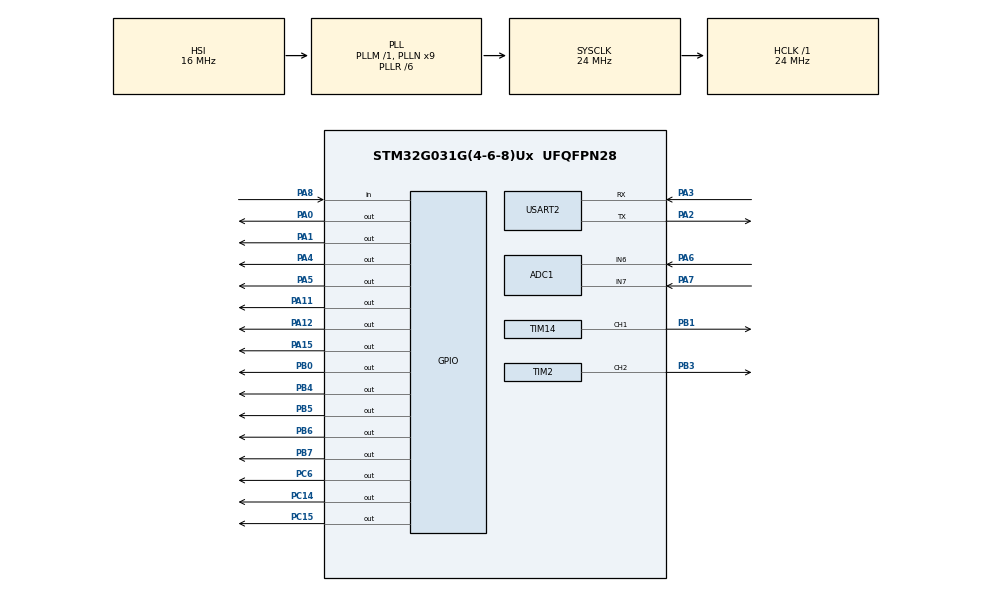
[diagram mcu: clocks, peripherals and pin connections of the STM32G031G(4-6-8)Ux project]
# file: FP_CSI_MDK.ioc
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ADC1.Channel-2\#ChannelRegularConversion=ADC_CHANNEL_6
ADC1.Channel-3\#ChannelRegularConversion=ADC_CHANNEL_7
ADC1.ClockPrescaler=ADC_CLOCK_ASYNC_DIV2
ADC1.ContinuousConvMode=ENABLE
ADC1.DMAContinuousRequests=ENABLE
ADC1.DiscontinuousConvMode=DISABLE
ADC1.EOCSelection=ADC_EOC_SEQ_CONV
ADC1.NbrOfConversion=2
ADC1.NbrOfConversionFlag=1
ADC1.Rank-2\#ChannelRegularConversion=1
ADC1.Rank-3\#ChannelRegularConversion=2
ADC1.SamplingTime-2\#ChannelRegularConversion=ADC_SAMPLINGTIME_COMMON_1
ADC1.SamplingTime-3\#ChannelRegularConversion=ADC_SAMPLINGTIME_COMMON_1
ADC1.ScanConvMode=ADC_SCAN_ENABLE
ADC1.SelectedChannel=ADC_CHANNEL_6|ADC_CHANNEL_7
ADC1.Sequencer=FULLY_CONFIGURABLE
ADC1.master=1
Dma.ADC1.0.Direction=DMA_PERIPH_TO_MEMORY
Dma.ADC1.0.EventEnable=DISABLE
Dma.ADC1.0.Instance=DMA1_Channel1
Dma.ADC1.0.MemDataAlignment=DMA_MDATAALIGN_HALFWORD
Dma.ADC1.0.MemInc=DMA_MINC_ENABLE
Dma.ADC1.0.Mode=DMA_CIRCULAR
Dma.ADC1.0.PeriphDataAlignment=DMA_PDATAALIGN_HALFWORD
Dma.ADC1.0.PeriphInc=DMA_PINC_DISABLE
Dma.ADC1.0.Polarity=HAL_DMAMUX_REQ_GEN_RISING
Dma.ADC1.0.Priority=DMA_PRIORITY_LOW
Dma.ADC1.0.RequestNumber=1
Dma.ADC1.0.SignalID=NONE
Dma.ADC1.0.SyncEnable=DISABLE
Dma.ADC1.0.SyncPolarity=HAL_DMAMUX_SYNC_NO_EVENT
Dma.ADC1.0.SyncRequestNumber=1
Dma.ADC1.0.SyncSignalID=NONE
Dma.Request0=ADC1
Mcu.Family=STM32G0
Mcu.Name=STM32G031G(4-6-8)Ux
Mcu.Package=UFQFPN28
NVIC.ADC1_IRQn=true\:0\:0\:false\:false\:true\:true\:true
NVIC.DMA1_Channel1_IRQn=true\:0\:0\:false\:false\:true\:false\:true
NVIC.EXTI4_15_IRQn=true\:0\:0\:false\:false\:true\:true\:true
NVIC.TIM1_BRK_UP_TRG_COM_IRQn=true\:0\:0\:false\:false\:true\:true\:true
NVIC.USART2_IRQn=true\:0\:0\:false\:false\:true\:true\:true
PA0.GPIO_PuPd=GPIO_PULLUP
PA0.Signal=GPIO_Output
PA1.GPIO_PuPd=GPIO_PULLUP
PA1.Signal=GPIO_Output
PA11\ [PA9].GPIO_PuPd=GPIO_PULLUP
PA11\ [PA9].Signal=GPIO_Output
PA12\ [PA10].GPIO_PuPd=GPIO_PULLUP
PA12\ [PA10].Signal=GPIO_Output
PA15.GPIO_PuPd=GPIO_PULLUP
PA15.Signal=GPIO_Output
PA2.Mode=Asynchronous
PA2.Signal=USART2_TX
PA3.Mode=Asynchronous
PA3.Signal=USART2_RX
PA4.GPIO_PuPd=GPIO_PULLUP
PA4.Signal=GPIO_Output
PA5.GPIO_PuPd=GPIO_PULLUP
PA5.Signal=GPIO_Output
PA6.Signal=SharedAnalog_PA6
PA7.Signal=SharedAnalog_PA7
PA8.GPIO_ModeDefaultEXTI=GPIO_MODE_IT_FALLING
PA8.GPIO_PuPd=GPIO_PULLUP
PA8.Signal=SharedStack_PA8
PA8.Stacked=true
PB0.GPIO_PuPd=GPIO_PULLUP
PB0.Signal=GPIO_Output
PB1.Signal=S_TIM14_CH1
PB3.Signal=S_TIM2_CH2
PB4.GPIO_PuPd=GPIO_PULLUP
PB4.Signal=GPIO_Output
PB5.GPIO_PuPd=GPIO_PULLUP
PB5.Signal=GPIO_Output
PB6.GPIO_PuPd=GPIO_PULLUP
PB6.Signal=GPIO_Output
PB7.GPIO_PuPd=GPIO_PULLUP
PB7.Signal=GPIO_Output
PC14-OSC32_IN\ (PC14).GPIO_PuPd=GPIO_PULLUP
PC14-OSC32_IN\ (PC14).Signal=GPIO_Output
PC15-OSC32_OUT\ (PC15).GPIO_PuPd=GPIO_PULLUP
PC15-OSC32_OUT\ (PC15).Signal=GPIO_Output
PC6.GPIO_PuPd=GPIO_PULLUP
PC6.Signal=GPIO_Output
ProjectManager.HeapSize=0x200
ProjectManager.StackSize=0x400
ProjectManager.TargetToolchain=MDK-ARM V5.27
RCC.ADCFreq_Value=24000000
RCC.AHBFreq_Value=24000000
RCC.CortexFreq_Value=24000000
RCC.EXTERNAL_CLOCK_VALUE=12288000
RCC.HCLKFreq_Value=24000000
RCC.HSE_VALUE=8000000
RCC.HSI_VALUE=16000000
RCC.LSE_VALUE=32768
RCC.PLLN=9
RCC.PLLR=RCC_PLLR_DIV6
RCC.SYSCLKFreq_VALUE=24000000
RCC.SYSCLKSource=RCC_SYSCLKSOURCE_PLLCLK
RCC.VCOOutputFreq_Value=144000000
SH.S_TIM14_CH1.0=TIM14_CH1,PWM Generation1 CH1
SH.S_TIM2_CH2.0=TIM2_CH2,PWM Generation2 CH2
SH.SharedAnalog_PA6.0=GPIO_Analog
SH.SharedAnalog_PA6.1=ADC1_IN6,IN6
SH.SharedAnalog_PA7.0=GPIO_Analog
SH.SharedAnalog_PA7.1=ADC1_IN7,IN7
SH.SharedStack_PA8.0=GPIO_Input+0
SH.SharedStack_PA8.1=GPIO_EXTI8
TIM1.Period=1000
TIM1.Prescaler=12-1
TIM14.Channel=TIM_CHANNEL_1
TIM2.Channel-PWM\ Generation2\ CH2=TIM_CHANNEL_2
USART2.VirtualMode-Asynchronous=VM_ASYNC
VP_TIM14_VS_ClockSourceINT.Mode=Enable_Timer
VP_TIM1_VS_ClockSourceINT.Mode=Internal
VP_TIM2_VS_ClockSourceINT.Mode=Internal
board=custom

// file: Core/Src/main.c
/* USER CODE BEGIN Header */
/**
  ******************************************************************************
  * @file           : main.c
  * @brief          : Main program body
  ******************************************************************************
  * @attention
  *
  * <h2><center>&copy; Copyright (c) 2021 STMicroelectronics.
  * All rights reserved.</center></h2>
  *
  * This software component is licensed by ST under BSD 3-Clause license,
  * the "License"; You may not use this file except in compliance with the
  * License. You may obtain a copy of the License at:
  *                        opensource.org/licenses/BSD-3-Clause
  *
  ******************************************************************************
  */
/* USER CODE END Header */
#include "main.h"
#include "adc.h"
#include "dma.h"
#include "tim.h"
#include "usart.h"
#include "gpio.h"

void SystemClock_Config(void);

int main(void)
{

  /* MCU Configuration--------------------------------------------------------*/

  /* Reset of all peripherals, Initializes the Flash interface and the Systick. */
  HAL_Init();

  /* Configure the system clock */
  SystemClock_Config();

  /* Initialize all configured peripherals */
  MX_GPIO_Init();
  MX_DMA_Init();
  MX_ADC1_Init();
  MX_TIM2_Init();
  MX_TIM14_Init();
  MX_USART2_UART_Init();
  MX_TIM1_Init();
  /* USER CODE BEGIN 2 */
  ADC_InitValue();

  BlueCmdInit();
  __HAL_TIM_CLEAR_IT(&htim1,TIM_IT_UPDATE);
  HAL_TIM_Base_Start_IT(&htim1);

   SENSOR_ORIGIN_DetectPos();
   SENSOR_FilterNumbers_DetectPos();
  /* USER CODE END 2 */

  /* Infinite loop */
  while (1)
  {

    /* USER CODE BEGIN 3 */
//      UART_TRANSMIT_TO_PC_DATA();
//      SENSOR_ORIGIN_DetectPos();
//	  SENSOR_FilterNumbers_DetectPos();
      //FilterNumbers_Calculate();
      Bluetooth_Decode();
     // MOTOR_Run();
  }
  /* USER CODE END 3 */
}

void SystemClock_Config(void)
{
  RCC_OscInitTypeDef RCC_OscInitStruct = {0};
  RCC_ClkInitTypeDef RCC_ClkInitStruct = {0};
  RCC_PeriphCLKInitTypeDef PeriphClkInit = {0};

  /** Configure the main internal regulator output voltage
  */
  HAL_PWREx_ControlVoltageScaling(PWR_REGULATOR_VOLTAGE_SCALE1);
  /** Initializes the RCC Oscillators according to the specified parameters
  * in the RCC_OscInitTypeDef structure.
  */
  RCC_OscInitStruct.OscillatorType = RCC_OSCILLATORTYPE_HSI;
  RCC_OscInitStruct.HSIState = RCC_HSI_ON;
  RCC_OscInitStruct.HSIDiv = RCC_HSI_DIV1;
  RCC_OscInitStruct.HSICalibrationValue = RCC_HSICALIBRATION_DEFAULT;
  RCC_OscInitStruct.PLL.PLLState = RCC_PLL_ON;
  RCC_OscInitStruct.PLL.PLLSource = RCC_PLLSOURCE_HSI;
  RCC_OscInitStruct.PLL.PLLM = RCC_PLLM_DIV1;
  RCC_OscInitStruct.PLL.PLLN = 9;
  RCC_OscInitStruct.PLL.PLLP = RCC_PLLP_DIV2;
  RCC_OscInitStruct.PLL.PLLQ = RCC_PLLQ_DIV2;
  RCC_OscInitStruct.PLL.PLLR = RCC_PLLR_DIV6;
  if (HAL_RCC_OscConfig(&RCC_OscInitStruct) != HAL_OK)
  {
    Error_Handler();
  }
  /** Initializes the CPU, AHB and APB buses clocks
  */
  RCC_ClkInitStruct.ClockType = RCC_CLOCKTYPE_HCLK|RCC_CLOCKTYPE_SYSCLK
                              |RCC_CLOCKTYPE_PCLK1;
  RCC_ClkInitStruct.SYSCLKSource = RCC_SYSCLKSOURCE_PLLCLK;
  RCC_ClkInitStruct.AHBCLKDivider = RCC_SYSCLK_DIV1;
  RCC_ClkInitStruct.APB1CLKDivider = RCC_HCLK_DIV1;

  if (HAL_RCC_ClockConfig(&RCC_ClkInitStruct, FLASH_LATENCY_0) != HAL_OK)
  {
    Error_Handler();
  }
  /** Initializes the peripherals clocks
  */
  PeriphClkInit.PeriphClockSelection = RCC_PERIPHCLK_ADC|RCC_PERIPHCLK_TIM1;
  PeriphClkInit.AdcClockSelection = RCC_ADCCLKSOURCE_SYSCLK;
  PeriphClkInit.Tim1ClockSelection = RCC_TIM1CLKSOURCE_PCLK1;
  if (HAL_RCCEx_PeriphCLKConfig(&PeriphClkInit) != HAL_OK)
  {
    Error_Handler();
  }
}

void Error_Handler(void)
{
  __disable_irq();
  while (1)
  {
  }
}

/************************ (C) COPYRIGHT STMicroelectronics *****END OF FILE****/
